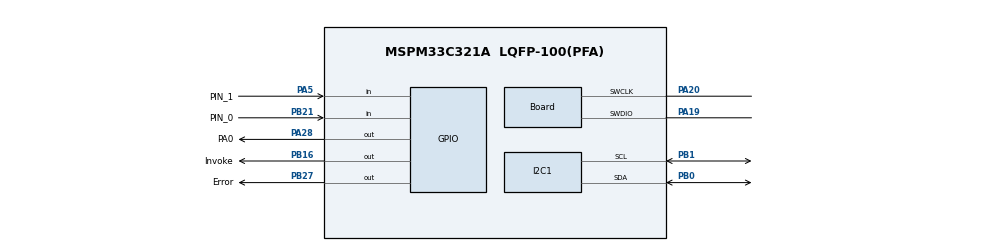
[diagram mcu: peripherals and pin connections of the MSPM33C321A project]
//@cliArgs --device "MSPM33C321A" --package "LQFP-100(PFA)" --part "Default"
//@v2CliArgs --device "MSPM33C321A" --package "LQFP-100(PFA)"
// @cliArgs --board /ti/boards/LP_MSPM33C321A --rtos nortos

/**
 * Import the modules used in this configuration.
 */
const Board         = scripting.addModule("/ti/driverlib/Board");
const CRCP          = scripting.addModule("/ti/driverlib/CRCP");
const GPIO          = scripting.addModule("/ti/driverlib/GPIO", {}, false);
const GPIO1         = GPIO.addInstance();
const GPIO2         = GPIO.addInstance();
const GPIO3         = GPIO.addInstance();
const GPIO4         = GPIO.addInstance();
const I2C           = scripting.addModule("/ti/driverlib/I2C", {}, false);
const I2C1          = I2C.addInstance();
const SYSCTL        = scripting.addModule("/ti/driverlib/SYSCTL");
const ProjectConfig = scripting.addModule("/ti/project_config/ProjectConfig");

/**
 * Write custom configuration values to the imported modules.
 */
Board.peripheral.$assign          = "DEBUGSS";
Board.peripheral.swclkPin.$assign = "PA20";
Board.peripheral.swdioPin.$assign = "PA19";

CRCP.profile = "CONFIG_PROFILE_2";

GPIO1.port                                  = "PORTB";
GPIO1.$name                                 = "GPIO_Button";
GPIO1.associatedPins[0].$name               = "PIN_0";
GPIO1.associatedPins[0].assignedPortSegment = "Upper";
GPIO1.associatedPins[0].assignedPin         = "21";
GPIO1.associatedPins[0].internalResistor    = "PULL_UP";
GPIO1.associatedPins[0].direction           = "INPUT";
GPIO1.associatedPins[0].pin.$assign         = "PB21";

GPIO2.$name                                 = "GPIO_BSL";
GPIO2.port                                  = "PORTB";
GPIO2.associatedPins[0].assignedPin         = "16";
GPIO2.associatedPins[0].assignedPortSegment = "Upper";
GPIO2.associatedPins[0].$name               = "Invoke";
GPIO2.associatedPins[0].pin.$assign         = "PB16";

GPIO3.$name                                 = "GPIO_LED";
GPIO3.associatedPins.create(2);
GPIO3.associatedPins[0].assignedPort        = "PORTA";
GPIO3.associatedPins[0].assignedPortSegment = "Upper";
GPIO3.associatedPins[0].assignedPin         = "28";
GPIO3.associatedPins[0].$name               = "PA0";
GPIO3.associatedPins[0].pin.$assign         = "PA28";
GPIO3.associatedPins[1].$name               = "Error";
GPIO3.associatedPins[1].assignedPort        = "PORTB";
GPIO3.associatedPins[1].assignedPortSegment = "Upper";
GPIO3.associatedPins[1].assignedPin         = "27";
GPIO3.associatedPins[1].pin.$assign         = "PB27";

GPIO4.$name                                 = "GPIO_LEDS";
GPIO4.associatedPins[0].$name               = "PIN_1";
GPIO4.associatedPins[0].assignedPort        = "PORTA";
GPIO4.associatedPins[0].assignedPortSegment = "Lower";
GPIO4.associatedPins[0].assignedPin         = "5";
GPIO4.associatedPins[0].direction           = "INPUT";
GPIO4.associatedPins[0].pin.$assign         = "PA5";

I2C1.$name                             = "I2C";
I2C1.basicEnableController             = true;
I2C1.advControllerRXFIFOTRIG           = "1_4_FULL";
I2C1.basicControllerStandardBusSpeed   = "Fast";
I2C1.peripheral.$assign                = "UC1_0";
I2C1.peripheral.sdaPin.$assign         = "PB0";
I2C1.peripheral.sclPin.$assign         = "PB1";
I2C1.sdaPinConfig.$name                = "ti_driverlib_gpio_GPIOPinGeneric0";
I2C1.sdaPinConfig.hideOutputInversion  = scripting.forceWrite(false);
I2C1.sdaPinConfig.onlyInternalResistor = scripting.forceWrite(false);
I2C1.sdaPinConfig.passedPeripheralType = scripting.forceWrite("Digital");
I2C1.sdaPinConfig.enableConfig         = true;
I2C1.sdaPinConfig.internalResistor     = "PULL_UP";
I2C1.sclPinConfig.$name                = "ti_driverlib_gpio_GPIOPinGeneric1";
I2C1.sclPinConfig.hideOutputInversion  = scripting.forceWrite(false);
I2C1.sclPinConfig.onlyInternalResistor = scripting.forceWrite(false);
I2C1.sclPinConfig.passedPeripheralType = scripting.forceWrite("Digital");
I2C1.sclPinConfig.enableConfig         = true;
I2C1.sclPinConfig.internalResistor     = "PULL_UP";

SYSCTL.peripheral.$assign = "SYSCTL";

ProjectConfig.migrationCondition = true;
